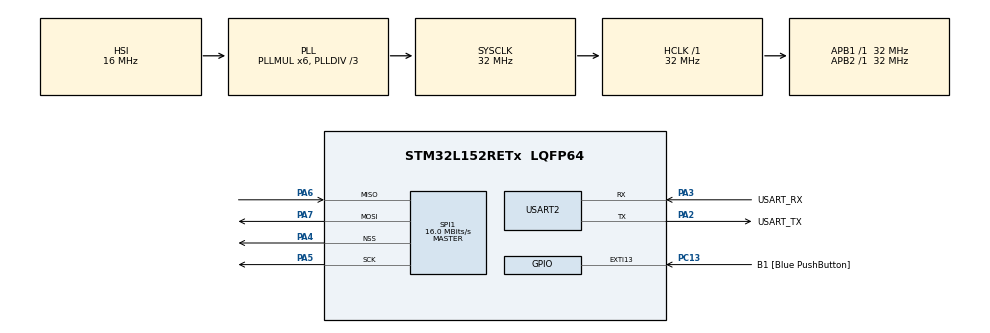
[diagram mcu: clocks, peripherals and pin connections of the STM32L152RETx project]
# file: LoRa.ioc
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FREERTOS.Tasks01=defaultTask,24,128,StartDefaultTask,Default,NULL,Dynamic,NULL,NULL;loraTask,8,512,LoRaTaskRun,As weak,NULL,Dynamic,NULL,NULL
Mcu.Family=STM32L1
Mcu.Name=STM32L152RETx
Mcu.Package=LQFP64
NVIC.PriorityGroup=NVIC_PRIORITYGROUP_4
NVIC.TIM2_IRQn=true\:0\:0\:false\:false\:true\:false\:false\:true
NVIC.TimeBase=TIM2_IRQn
NVIC.TimeBaseIP=TIM2
PA13.GPIO_Label=TMS
PA13.Mode=Serial_Wire
PA13.Signal=SYS_JTMS-SWDIO
PA14.GPIO_Label=TCK
PA14.Mode=Serial_Wire
PA14.Signal=SYS_JTCK-SWCLK
PA2.GPIO_Label=USART_TX
PA2.Mode=Asynchronous
PA2.Signal=USART2_TX
PA3.GPIO_Label=USART_RX
PA3.Mode=Asynchronous
PA3.Signal=USART2_RX
PA4.Mode=NSS_Signal_Hard_Output
PA4.Signal=SPI1_NSS
PA5.Mode=Full_Duplex_Master
PA5.Signal=SPI1_SCK
PA6.Mode=Full_Duplex_Master
PA6.Signal=SPI1_MISO
PA7.Mode=Full_Duplex_Master
PA7.Signal=SPI1_MOSI
PB3.GPIO_Label=SWO
PB3.Signal=SYS_JTDO-TRACESWO
PC13-WKUP2.GPIO_Label=B1 [Blue PushButton]
PC13-WKUP2.Signal=GPXTI13
PC14-OSC32_IN.Mode=LSE-External-Oscillator
PC14-OSC32_IN.Signal=RCC_OSC32_IN
PC15-OSC32_OUT.Mode=LSE-External-Oscillator
PC15-OSC32_OUT.Signal=RCC_OSC32_OUT
PH0-OSC_IN.Mode=HSE-External-Clock-Source
PH0-OSC_IN.Signal=RCC_OSC_IN
PH1-OSC_OUT.Signal=RCC_OSC_OUT
ProjectManager.HeapSize=0x200
ProjectManager.StackSize=0x400
ProjectManager.TargetToolchain=STM32CubeIDE
RCC.48MHZClocksFreq_Value=48000000
RCC.AHBFreq_Value=32000000
RCC.APB1Freq_Value=32000000
RCC.APB1TimFreq_Value=32000000
RCC.APB2Freq_Value=32000000
RCC.APB2TimFreq_Value=32000000
RCC.HCLKFreq_Value=32000000
RCC.HSE_VALUE=8000000
RCC.HSI_VALUE=16000000
RCC.MSI_VALUE=2097000
RCC.PLLDIV=RCC_PLL_DIV3
RCC.PLLMUL=RCC_PLL_MUL6
RCC.RTCClockSelectionVirtual=RCC_RTCCLKSOURCE_LSE
RCC.SYSCLKFreq_VALUE=32000000
RCC.SYSCLKSource=RCC_SYSCLKSOURCE_PLLCLK
RCC.USBOutput=48000000
RCC.VCOOutputFreq_Value=96000000
SPI1.CalculateBaudRate=16.0 MBits/s
SPI1.Direction=SPI_DIRECTION_2LINES
SPI1.Mode=SPI_MODE_MASTER
SPI1.VirtualNSS=VM_NSSHARD
SPI1.VirtualType=VM_MASTER
USART2.VirtualMode=VM_ASYNC
VP_FREERTOS_VS_CMSIS_V2.Mode=CMSIS_V2
VP_RTC_VS_RTC_Activate.Mode=RTC_Enabled
VP_RTC_VS_RTC_Calendar.Mode=RTC_Calendar
VP_SYS_VS_tim2.Mode=TIM2
board=NUCLEO-L152RE

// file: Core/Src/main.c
/* USER CODE BEGIN Header */
/**
  ******************************************************************************
  * @file           : main.c
  * @brief          : Main program body
  ******************************************************************************
  * @attention
  *
  * <h2><center>&copy; Copyright (c) 2019 STMicroelectronics.
  * All rights reserved.</center></h2>
  *
  * This software component is licensed by ST under Ultimate Liberty license
  * SLA0044, the "License"; You may not use this file except in compliance with
  * the License. You may obtain a copy of the License at:
  *                             www.st.com/SLA0044
  *
  ******************************************************************************
  */
/* USER CODE END Header */

#include "main.h"
#include "cmsis_os.h"
#include "rtc.h"
#include "spi.h"
#include "usart.h"
#include "gpio.h"

void SystemClock_Config(void);
void MX_FREERTOS_Init(void);

int main(void)
{

  /* MCU Configuration--------------------------------------------------------*/

  /* Reset of all peripherals, Initializes the Flash interface and the Systick. */
  HAL_Init();

  /* Configure the system clock */
  SystemClock_Config();

  /* Initialize all configured peripherals */
  MX_GPIO_Init();
  MX_USART2_UART_Init();
  MX_RTC_Init();
  MX_SPI1_Init();
  /* USER CODE BEGIN 2 */
  LoRaTaskRun(NULL);
  asm ("bkpt");
  /* USER CODE END 2 */

  /* Call init function for freertos objects (in freertos.c) */
  MX_FREERTOS_Init();

  /* Start scheduler */
  osKernelStart();

  /* We should never get here as control is now taken by the scheduler */

  /* Infinite loop */
  while (1)
  {

  }
}

void SystemClock_Config(void)
{
  RCC_OscInitTypeDef RCC_OscInitStruct = {0};
  RCC_ClkInitTypeDef RCC_ClkInitStruct = {0};
  RCC_PeriphCLKInitTypeDef PeriphClkInit = {0};

  /** Configure the main internal regulator output voltage
  */
  __HAL_PWR_VOLTAGESCALING_CONFIG(PWR_REGULATOR_VOLTAGE_SCALE1);
  /** Initializes the CPU, AHB and APB busses clocks
  */
  RCC_OscInitStruct.OscillatorType = RCC_OSCILLATORTYPE_HSI|RCC_OSCILLATORTYPE_LSE;
  RCC_OscInitStruct.LSEState = RCC_LSE_ON;
  RCC_OscInitStruct.HSIState = RCC_HSI_ON;
  RCC_OscInitStruct.HSICalibrationValue = RCC_HSICALIBRATION_DEFAULT;
  RCC_OscInitStruct.PLL.PLLState = RCC_PLL_ON;
  RCC_OscInitStruct.PLL.PLLSource = RCC_PLLSOURCE_HSI;
  RCC_OscInitStruct.PLL.PLLMUL = RCC_PLL_MUL6;
  RCC_OscInitStruct.PLL.PLLDIV = RCC_PLL_DIV3;
  if (HAL_RCC_OscConfig(&RCC_OscInitStruct) != HAL_OK)
  {
    Error_Handler();
  }
  /** Initializes the CPU, AHB and APB busses clocks
  */
  RCC_ClkInitStruct.ClockType = RCC_CLOCKTYPE_HCLK|RCC_CLOCKTYPE_SYSCLK
                              |RCC_CLOCKTYPE_PCLK1|RCC_CLOCKTYPE_PCLK2;
  RCC_ClkInitStruct.SYSCLKSource = RCC_SYSCLKSOURCE_PLLCLK;
  RCC_ClkInitStruct.AHBCLKDivider = RCC_SYSCLK_DIV1;
  RCC_ClkInitStruct.APB1CLKDivider = RCC_HCLK_DIV1;
  RCC_ClkInitStruct.APB2CLKDivider = RCC_HCLK_DIV1;

  if (HAL_RCC_ClockConfig(&RCC_ClkInitStruct, FLASH_LATENCY_1) != HAL_OK)
  {
    Error_Handler();
  }
  PeriphClkInit.PeriphClockSelection = RCC_PERIPHCLK_RTC;
  PeriphClkInit.RTCClockSelection = RCC_RTCCLKSOURCE_LSE;
  if (HAL_RCCEx_PeriphCLKConfig(&PeriphClkInit) != HAL_OK)
  {
    Error_Handler();
  }
}

void HAL_TIM_PeriodElapsedCallback(TIM_HandleTypeDef *htim)
{
  if (htim->Instance == TIM2) {
    HAL_IncTick();
  }
}

void Error_Handler(void)
{
}

/************************ (C) COPYRIGHT STMicroelectronics *****END OF FILE****/

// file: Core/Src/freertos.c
/* USER CODE BEGIN Header */
/**
  ******************************************************************************
  * File Name          : freertos.c
  * Description        : Code for freertos applications
  ******************************************************************************
  * @attention
  *
  * <h2><center>&copy; Copyright (c) 2019 STMicroelectronics.
  * All rights reserved.</center></h2>
  *
  * This software component is licensed by ST under Ultimate Liberty license
  * SLA0044, the "License"; You may not use this file except in compliance with
  * the License. You may obtain a copy of the License at:
  *                             www.st.com/SLA0044
  *
  ******************************************************************************
  */
/* USER CODE END Header */

#include "FreeRTOS.h"
#include "task.h"
#include "main.h"
#include "cmsis_os.h"

osThreadId_t defaultTaskHandle;
osThreadId_t loraTaskHandle;

void StartDefaultTask(void *argument);
void LoRaTaskRun(void *argument);

void MX_FREERTOS_Init(void); /* (MISRA C 2004 rule 8.1) */

void MX_FREERTOS_Init(void) {
osKernelInitialize();

  /* Create the thread(s) */
  /* definition and creation of defaultTask */
  const osThreadAttr_t defaultTask_attributes = {
    .name = "defaultTask",
    .priority = (osPriority_t) osPriorityNormal,
    .stack_size = 128
  };
  defaultTaskHandle = osThreadNew(StartDefaultTask, NULL, &defaultTask_attributes);

  /* definition and creation of loraTask */
  const osThreadAttr_t loraTask_attributes = {
    .name = "loraTask",
    .priority = (osPriority_t) osPriorityLow,
    .stack_size = 512
  };
  loraTaskHandle = osThreadNew(LoRaTaskRun, NULL, &loraTask_attributes);

}

void StartDefaultTask(void *argument)
{

  for(;;)
  {
    osDelay(1);
  }
}

__weak void LoRaTaskRun(void *argument)
{
  for(;;)
  {
    osDelay(1);
  }
}

/************************ (C) COPYRIGHT STMicroelectronics *****END OF FILE****/
